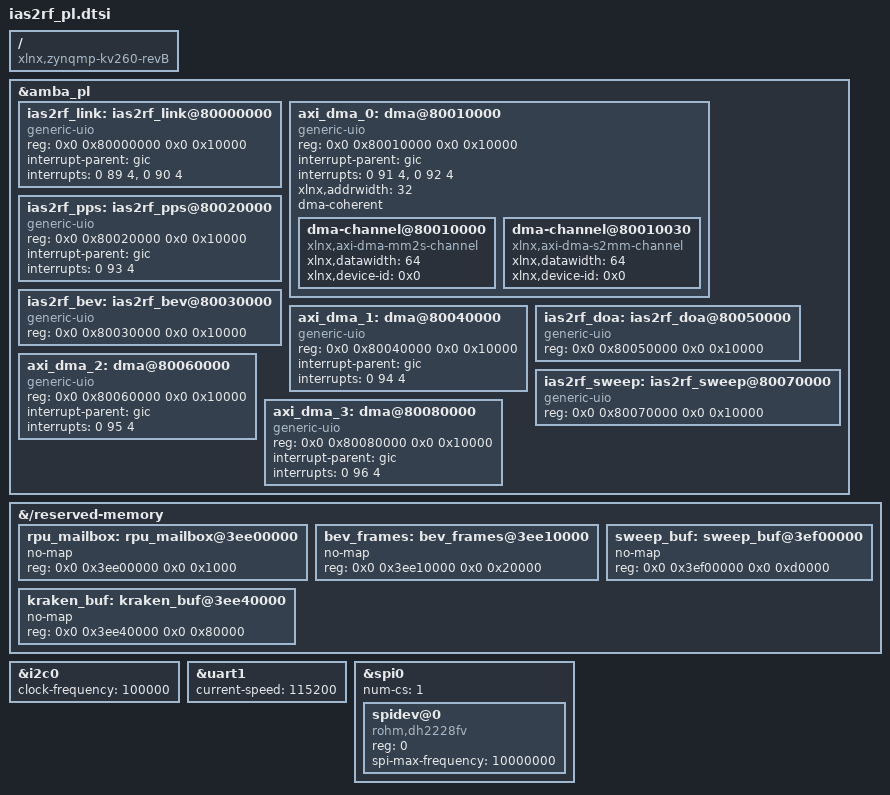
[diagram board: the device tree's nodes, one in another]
// SPDX-License-Identifier: BSD-2-Clause
// Devicetree overlay fragment for KV260 IAS1 PL Bitstream
// Exposes kria_pl_link CSRs via UIO, AXI DMA S2MM/MM2S via u-dma-buf / UIO, kria_pps and the fusion grid via UIO,
// PS EMIO I2C0 / SPI0 buses routed to the IAS2RF adapter and Pmod J2, and PS UART1 on EMIO to the
// front-end FPGA's debug console (dbg_uart) over the two Pmod spare lines: /dev/ttyPS1, 115200 8N1.

/dts-v1/;
/plugin/;

/ {
    compatible = "xlnx,zynqmp-kv260-revB", "xlnx,zynqmp-kv260", "xlnx,zynqmp";

    fragment@0 {
        target = <&amba_pl>;
        __overlay__ {
            #address-cells = <2>;
            #size-cells = <2>;

            ias2rf_link: ias2rf_link@80000000 {
                compatible = "generic-uio";
                reg = <0x0 0x80000000 0x0 0x10000>;
                interrupt-parent = <&gic>;
                interrupts = <0 89 4>, <0 90 4>;
                interrupt-names = "irq_fpga", "irq_link_up";
                status = "okay";
            };

            axi_dma_0: dma@80010000 {
                compatible = "generic-uio", "xlnx,axi-dma-7.1";
                #dma-cells = <1>;
                reg = <0x0 0x80010000 0x0 0x10000>;
                interrupt-parent = <&gic>;
                interrupts = <0 91 4>, <0 92 4>;
                interrupt-names = "s2mm_introut", "mm2s_introut";
                xlnx,addrwidth = /bits/ 8 <32>;
                dma-coherent;
                status = "okay";

                dma-channel@80010000 {
                    compatible = "xlnx,axi-dma-mm2s-channel";
                    xlnx,datawidth = <64>;
                    xlnx,device-id = <0x0>;
                };
                dma-channel@80010030 {
                    compatible = "xlnx,axi-dma-s2mm-channel";
                    xlnx,datawidth = <64>;
                    xlnx,device-id = <0x0>;
                };
            };

            /* GPS PPS capture and disciplined PPS generator (fpga/kria/kria_pps.v).
             * R5F core 0 owns it (sw/kria/r5f); Linux maps it read-only in practice,
             * for NOW (the PL clock both sides stamp the mailbox with). pl_ps_irq0[4]. */
            ias2rf_pps: ias2rf_pps@80020000 {
                compatible = "generic-uio";
                reg = <0x0 0x80020000 0x0 0x10000>;
                interrupt-parent = <&gic>;
                interrupts = <0 93 4>;
                interrupt-names = "pps";
                status = "okay";
            };

            /* Bird's-eye-view fusion grid (fpga/kria/kria_bev_axi.v): registers and command port. */
            ias2rf_bev: ias2rf_bev@80030000 {
                compatible = "generic-uio";
                reg = <0x0 0x80030000 0x0 0x10000>;
                status = "okay";
            };

            /* S2MM-only DMA for the grid's 64 KiB dumps, into bev_frames below. pl_ps_irq0[5]. */
            axi_dma_1: dma@80040000 {
                compatible = "generic-uio";
                reg = <0x0 0x80040000 0x0 0x10000>;
                interrupt-parent = <&gic>;
                interrupts = <0 94 4>;
                interrupt-names = "s2mm_introut";
                status = "okay";
            };

            /* KrakenSDR direction finding (fpga/kria/integrations/kria_doa.v): weights, covariance, Bartlett
             * spectrum and the steering table, 64 KiB of registers. */
            ias2rf_doa: ias2rf_doa@80050000 {
                compatible = "generic-uio";
                reg = <0x0 0x80050000 0x0 0x10000>;
                status = "okay";
            };

            /* MM2S-only DMA: the KrakenSDR's aligned snapshots from kraken_buf into kria_doa. pl_ps_irq0[6]. */
            axi_dma_2: dma@80060000 {
                compatible = "generic-uio";
                reg = <0x0 0x80060000 0x0 0x10000>;
                interrupt-parent = <&gic>;
                interrupts = <0 95 4>;
                interrupt-names = "mm2s_introut";
                status = "okay";
            };

            /* HackRF Pro sweep (fpga/kria/integrations/kria_sweep.v): window, twiddles, counters. */
            ias2rf_sweep: ias2rf_sweep@80070000 {
                compatible = "generic-uio";
                reg = <0x0 0x80070000 0x0 0x10000>;
                status = "okay";
            };

            /* DMA both ways for the sweep: USB blocks from sweep_buf in, 520-byte results back.
             * pl_ps_irq0[7] is its S2MM completion; MM2S is polled. */
            axi_dma_3: dma@80080000 {
                compatible = "generic-uio";
                reg = <0x0 0x80080000 0x0 0x10000>;
                interrupt-parent = <&gic>;
                interrupts = <0 96 4>;
                interrupt-names = "s2mm_introut";
                status = "okay";
            };
        };
    };

    /* Mailbox between Linux and R5F core 0 (sw/kria/core/src/mailbox.rs): 4 KiB at 0x3EE00000,
     * kept out of the kernel's memory map so /dev/mem may write it and the R5F (caches off) and
     * the A53s see the same bytes. Placed above the OpenAMP vrings Xilinx images use at
     * 0x3ED00000-0x3ED7FFFF. */
    fragment@4 {
        target-path = "/reserved-memory";
        __overlay__ {
            #address-cells = <2>;
            #size-cells = <2>;
            rpu_mailbox: rpu_mailbox@3ee00000 {
                no-map;
                reg = <0x0 0x3ee00000 0x0 0x1000>;
            };
            /* Two 64 KiB frames for the fusion grid's dumps (axi_dma_1 writes, Linux reads). */
            bev_frames: bev_frames@3ee10000 {
                no-map;
                reg = <0x0 0x3ee10000 0x0 0x20000>;
            };
            /* KrakenSDR CPI buffer: 2^15 snapshots of 16 bytes (axi_dma_2 reads). */
            kraken_buf: kraken_buf@3ee40000 {
                no-map;
                reg = <0x0 0x3ee40000 0x0 0x80000>;
            };
            /* HackRF sweep: 48 blocks of 16 KiB in (axi_dma_3 reads), then 48 results of 520 bytes out. */
            sweep_buf: sweep_buf@3ef00000 {
                no-map;
                reg = <0x0 0x3ef00000 0x0 0xd0000>;
            };
        };
    };

    /* EMIO I2C0 -> HK_SCL / HK_SDA (M24C02 EEPROM @ 0x50, TMP1075 / LM75) */
    fragment@1 {
        target = <&i2c0>;
        __overlay__ {
            status = "okay";
            clock-frequency = <100000>;
        };
    };

    /* EMIO UART1 -> Pmod J2 spare lines -> Artix dbg_uart (Rev08 G-1): /dev/ttyPS1.
     * The spare lines carry no GPIO any more: the radar DDC enable and the link/ADC ready flag
     * they used to carry are CSRs RADAR_CTRL[0] (0xE4) and RADAR_STATUS[5] (0xE8). */
    fragment@3 {
        target = <&uart1>;
        __overlay__ {
            status = "okay";
            current-speed = <115200>;
        };
    };

    /* EMIO SPI0 -> KV260 Pmod J2 (Artix secondary command SPI port) */
    fragment@2 {
        target = <&spi0>;
        __overlay__ {
            status = "okay";
            num-cs = <1>;
            spidev@0 {
                compatible = "rohm,dh2228fv";
                reg = <0>;
                spi-max-frequency = <10000000>;
            };
        };
    };
};
